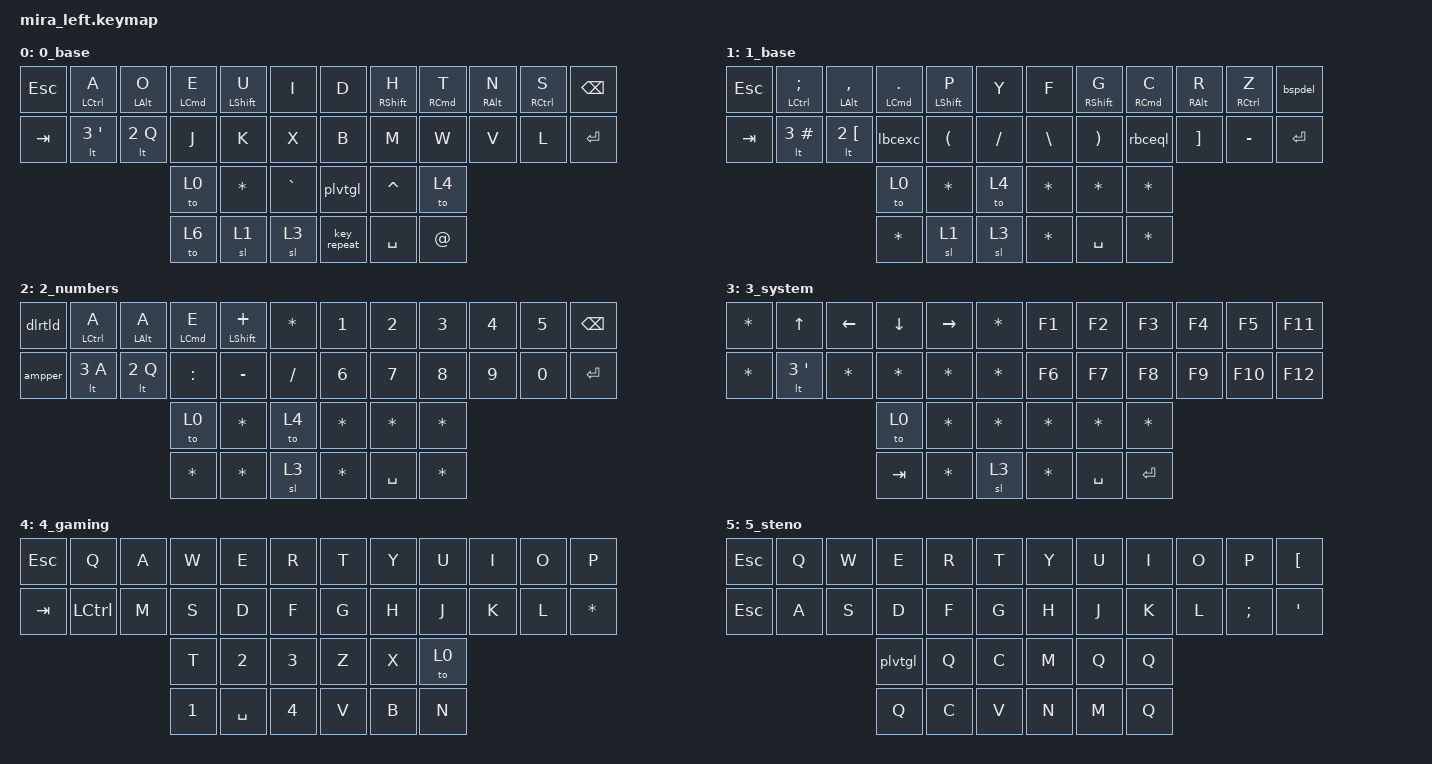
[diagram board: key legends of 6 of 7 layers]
#include <behaviors.dtsi>
#include <dt-bindings/zmk/keys.h>
#include <dt-bindings/zmk/bt.h>

/ {
        keymap {
		compatible = "zmk,keymap";

                // okay so seems like everything goes in here
                // mira_right.keymap is ignored, not even sure if i really need anything there but i dont want to acccidentally break it yk

                0_base {
                        bindings = <
                                &kp ESC        &mt LCTRL A    &mt LALT O     &mt LCMD E     &mt LSHFT U    &kp I            &kp D          &mt RSHFT H    &mt RCMD T     &mt RALT N     &mt RCTRL S     &kp BSPC
                                &kp TAB        &lt 3 SQT      &lt 2 Q        &kp J          &kp K          &kp X            &kp B          &kp M          &kp W          &kp V          &kp L           &kp RET
                                                                             &to 0          &kp STAR       &kp GRAVE        &plvtgl        &kp CARET      &to 4
                                                                             &to 6          &sl 1          &sl 3            &key_repeat    &kp SPACE      &kp AT
                        >;
                };

                1_base {
                        bindings = <
                                &kp ESC        &mt LCTRL SEMI &mt LALT COMMA &mt LCMD DOT   &mt LSHFT P    &kp Y            &kp F          &mt RSHFT G    &mt RCMD C      &mt RALT R    &mt RCTRL Z     &bspdel
                                &kp TAB        &lt 3 HASH     &lt 2 LBKT     &lbcexc        &kp LPAR       &kp FSLH         &kp BSLH       &kp RPAR       &rbceql         &kp RBKT      &kp MINUS       &kp RET
                                                                             &to 0          &kp STAR       &to 4            &kp STAR       &kp STAR       &kp STAR
                                                                             &kp STAR       &sl 1          &sl 3            &kp STAR       &kp SPACE      &kp STAR
                        >;
                };

                2_numbers {
                        bindings = <
                                &dlrtld        &mt LCTRL A    &mt LALT A     &mt LCMD E     &mt LSHFT PLUS &kp STAR         &kp N1         &kp N2         &kp N3          &kp N4        &kp N5          &kp BSPC
                                &ampper        &lt 3 A        &lt 2 Q        &kp COLON      &kp MINUS      &kp FSLH         &kp N6         &kp N7         &kp N8          &kp N9        &kp N0          &kp RET
                                                                             &to 0          &kp STAR       &to 4            &kp STAR       &kp STAR       &kp STAR 
                                                                             &kp STAR       &kp STAR       &sl 3            &kp STAR       &kp SPACE      &kp STAR
                        >;
                };

                3_system {
                        bindings = <
                                &kp STAR &kp UP    &kp LEFT &kp DOWN &kp RIGHT &kp STAR      &kp F1 &kp F2 &kp F3 &kp F4 &kp F5   &kp F11 
                                &kp STAR &lt 3 SQT &kp STAR &kp STAR &kp STAR  &kp STAR      &kp F6 &kp F7 &kp F8 &kp F9 &kp F10  &kp F12
                                                            &to 0    &kp STAR  &kp STAR      &kp STAR &kp STAR  &kp STAR 
                                                            &kp TAB  &kp STAR  &sl 3         &kp STAR &kp SPACE &kp RET  
                        >;
                };

                4_gaming {
                        bindings = <
                                &kp ESC &kp Q     &kp A &kp W  &kp E     &kp R         &kp T &kp Y &kp U &kp I &kp O &kp P
                                &kp TAB &kp LCTRL &kp M &kp S  &kp D     &kp F         &kp G &kp H &kp J &kp K &kp L &kp STAR 
                                                        &kp T  &kp N2    &kp N3        &kp Z &kp X &to 0 
                                                        &kp N1 &kp SPACE &kp N4        &kp V &kp B &kp N 
                        >;
                };

                5_steno {
                        bindings = <
                                &kp ESC &kp Q &kp W &kp E   &kp R &kp T         &kp Y &kp U &kp I &kp O &kp P    &kp LBKT
                                &kp ESC &kp A &kp S &kp D   &kp F &kp G         &kp H &kp J &kp K &kp L &kp SEMI &kp APOS 
                                                    &plvtgl &kp Q &kp C         &kp M &kp Q &kp Q
                                                    &kp Q   &kp C &kp V         &kp N &kp M &kp Q 
                        >;
                }; 
                
                6_bluetooth {
                        bindings = <
                                &trans         &trans         &trans         &trans         &trans         &trans         &bt BT_CLR_ALL &bt BT_PRV     &bt BT_NXT     &bt BT_CLR     &trans         &trans
                                &trans         &trans         &trans         &trans         &trans         &trans         &bt BT_SEL 0   &bt BT_SEL 1   &bt BT_SEL 2   &bt BT_SEL 3   &trans         &trans
                                &trans         &trans         &trans         &trans         &trans         &trans         &trans         &trans         &trans
                                                                             &trans         &trans         &trans         &trans         &trans         &trans
                        >;
                };
                
                /*
                empty {
                        bindings = <
                                &              &              &              &              &              &              &              &              &              &              &              &
                                &              &              &              &              &              &              &              &              &              &              &              &
                                &              &              &              &              &              &              &              &              &
                                                                             &              &              &              &              &              &
                        >;
                };
                */
        };

        macros {
                plvtgl: plover_toggle {
                        wait-ms = <5>;
                        tap-ms = <5>;
                        compatible = "zmk,behavior-macro";
                        #binding-cells = <0>;
                        bindings = <&macro_tap &tog 5>, <&macro_press &kp E &kp R &kp F &kp V &kp O &kp L>, <&macro_release &kp E &kp R &kp F &kp V &kp O &kp L>;
                };
        };

        behaviors {
                mt: mod_tap {
                        compatible = "zmk,behavior-hold-tap";
                        #binding-cells = <2>;
                        flavor = "balanced"; // fixes rolling issues, mandatory for home row mods imo
                        tapping-term-ms = <200>; // default
                        require-prior-idle-ms = <200>; // makes it always do tap when actively typing quickly
                        quick-tap-ms = <150>;
                        //retro-tap; // probably not needed // bad on windows key
                        bindings = <&kp>, <&kp>;
                };       
                lt: layer_tap {
                        compatible = "zmk,behavior-hold-tap";
                        #binding-cells = <2>;
                        flavor = "balanced"; // fixes rolling issues, mandatory for home row mods imo
                        tapping-term-ms = <200>; // default
                        //require-prior-idle-ms = <200>; // hm,,,
                        quick-tap-ms = <150>;
                        //retro-tap; // probably not needed // bad on windows key
                        //bindings = <&kp>, <&kp>;
                };

                dlrtld: dollar_tilde {
                        compatible = "zmk,behavior-mod-morph";
                        #binding-cells = <0>;
                        bindings = <&kp DOLLAR>, <&kp TILDE>;
                        mods = <(MOD_LSFT|MOD_RSFT)>;
                };                                      
                ampper: ampersand_percent {
                        compatible = "zmk,behavior-mod-morph";
                        #binding-cells = <0>;
                        bindings = <&kp AMPERSAND>, <&kp PERCENT>;
                        mods = <(MOD_LSFT|MOD_RSFT)>;
                };                                      
                lbkpnt: leftbracket_printscreen {
                        compatible = "zmk,behavior-mod-morph";
                        #binding-cells = <0>;
                        bindings = <&kp LEFT_BRACKET>, <&kp PRINTSCREEN>;
                        mods = <(MOD_LSFT|MOD_RSFT)>;
                };                          
                lbcexc: leftbrace_exclamation {
                        compatible = "zmk,behavior-mod-morph";
                        #binding-cells = <0>;
                        bindings = <&kp LEFT_BRACE>, <&kp EXCLAMATION>;
                        mods = <(MOD_LSFT|MOD_RSFT)>;
                };                          
                plsstr: plus_star {
                        compatible = "zmk,behavior-mod-morph";
                        #binding-cells = <0>;
                        bindings = <&kp PLUS>, <&kp STAR>;
                        mods = <(MOD_LSFT|MOD_RSFT)>;
                };               
                rbceql: rightbrace_equal {
                        compatible = "zmk,behavior-mod-morph";
                        #binding-cells = <0>;
                        bindings = <&kp RIGHT_BRACE>, <&kp EQUAL>;
                        mods = <(MOD_LSFT|MOD_RSFT)>;
                };                 
                atscar: at_caret {
                        compatible = "zmk,behavior-mod-morph";
                        #binding-cells = <0>;
                        bindings = <&kp AT>, <&kp CARET>;
                        mods = <(MOD_LSFT|MOD_RSFT)>;
                };
                bspdel: backspace_delete {
                        compatible = "zmk,behavior-mod-morph";
                        #binding-cells = <0>;
                        bindings = <&kp BACKSPACE>, <&kp DELETE>;
                        mods = <(MOD_LALT|MOD_RALT)>;
                };
        };
};
